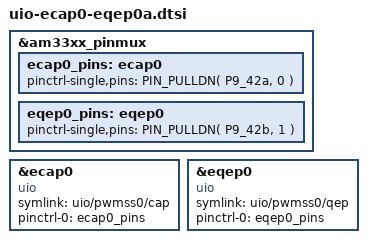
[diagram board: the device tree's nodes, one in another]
#include "bone/black.h"
#include "subarctic/uio/pwmss0.dtsi"  // make &epwmss0 usable for uio

// This enables both ecap0 and eqep0 on P9.42 for flexibiliy, allowing
// - using eCAP as PWM output and eQEP for monitoring, or
// - using eCAP and/or eQEP to perform measurements on an external signal

// disable cape-universal for pins used:
USES_PIN( P9_42 );  // P9_42a  ecap 0 in/out
USES_PIN( P9_92 );  // P9_42b  eqep 0 in A

&am33xx_pinmux {
        ecap0_pins: ecap0 {
                pinctrl-single,pins = <
                        PIN_PULLDN( P9_42a, 0 )  // ecap 0 in/out
                >;
        };

        eqep0_pins: eqep0 {
                pinctrl-single,pins = <
                        PIN_PULLDN( P9_42b, 1 )  // eqep 0 in A
                >;
        };
};

&ecap0 {
        status = "okay";

        compatible = "uio";
        symlink = "uio/pwmss0/cap";

        pinctrl-names = "default";
        pinctrl-0 = <&ecap0_pins>;
};

&eqep0 {
        status = "okay";

        compatible = "uio";
        symlink = "uio/pwmss0/qep";

        pinctrl-names = "default";
        pinctrl-0 = <&eqep0_pins>;
};
